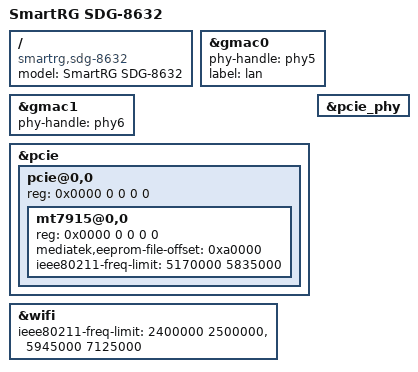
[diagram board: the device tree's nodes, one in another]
// SPDX-License-Identifier: (GPL-2.0 OR MIT)
/*
 * Copyright (C) 2022 SmartRG Inc.
 * Author: Chad Monroe <chad.monroe@smartrg.com>
 */

#include "mt7986a-smartrg-bonanza-peak.dtsi"

/ {
	model = "SmartRG SDG-8632";
	compatible = "smartrg,sdg-8632", "mediatek,mt7986a";
};

&gmac0 {
	phy-handle = <&phy5>;

	label = "lan";
};

&gmac1 {
	phy-handle = <&phy6>;
};

&pcie {
	status = "okay";

	pcie@0,0 {
		reg = <0x0000 0 0 0 0>;

		mt7915@0,0 {
			reg = <0x0000 0 0 0 0>;
			mediatek,eeprom-file-offset = <0xa0000>;
			ieee80211-freq-limit = <5170000 5835000>;
		};
	};
};

&pcie_phy {
	status = "okay";
};

&wifi {
	ieee80211-freq-limit = <2400000 2500000>, <5945000 7125000>;
};
